# f2838x_usb_regs register map
Vendor: Texas Instruments
Peripheral module from a debugger description file (folder C2000).
Address unit: 16 bits
Registers are 8-bit, read-write, no defined reset value unless marked. A register's access mark holds for its fields unless they carry their own. Offsets are as the file gives them; lines under a group give offsets from that group; [hi:lo] are bit positions; {n}, {i} and the like mark numbered series; 'fields as' and 'values as' point back to an identical list; <NAME> marks a mode.

## USB_REGS — USB Registers
0x00 USBFADDR — USB Device Functional Address
  [6:0] FUNCADDR — Functional Address
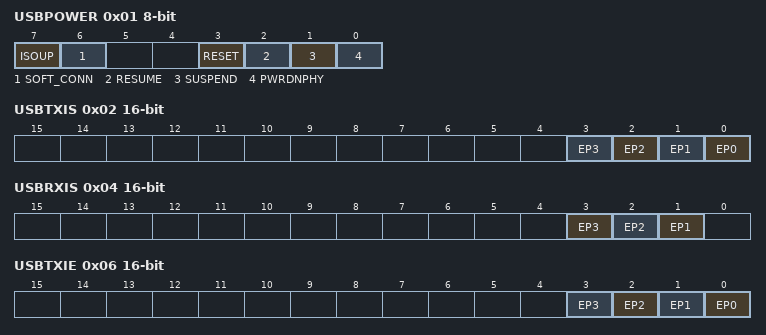
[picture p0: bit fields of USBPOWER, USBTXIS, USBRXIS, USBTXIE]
0x01 USBPOWER
  [7] ISOUP — Isochronous Update
  [6] SOFT_CONN — Soft Connect/Disconnect
  [3] RESET — Enable Reset Signaling
  [2] RESUME — Enable Resume Signaling
  [1] SUSPEND — Enable Suspend
  [0] PWRDNPHY — Power Down PHY
0x02 USBTXIS 16-bit ro — USB Transmit Interrupt Status
  [n] EP{n} (n=0..3) — Transmit Endpoint {n} Interrupt
0x04 USBRXIS 16-bit ro — USB Receive Interrupt Status
  [3] EP3 — Recieve Endpoint 3 Interrupt
  [2] EP2 — Recieve Endpoint 2 Interrupt
  [1] EP1 — Recieve Endpoint 1 Interrupt
0x06 USBTXIE 16-bit — USB Transmit Interrupt Enable
  [n] EP{n} (n=0..3) — Transmit Endpoint {n} Interrupt Enable
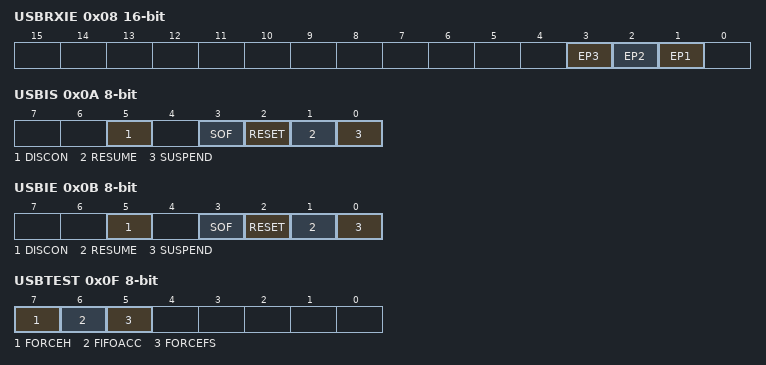
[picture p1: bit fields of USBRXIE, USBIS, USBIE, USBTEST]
0x08 USBRXIE 16-bit — USB Receive Interrupt Enable
  [3] EP3 — Recieve Endpoint 3 Interrupt Enable
  [2] EP2 — Recieve Endpoint 2 Interrupt Enable
  [1] EP1 — Recieve Endpoint 1 Interrupt Enable
0x0A USBIS access per field — USB General Interrupt Status
  [5] DISCON rw — Session Disconnect
  [3] SOF rw — Start of frame
  [2] RESET rw — RESET Signaling Detected
  [1] RESUME rw — RESUME Signaling Detected.
  [0] SUSPEND ro — SUSPEND Signaling Detected
0x0B USBIE access per field — USB Interrupt Enable
  fields as USBIS
0x0C USBFRAME 16-bit ro — USB Frame Value
  [10:0] FRAME — Frame Number
0x0E USBEPIDX — USB Endpoint Index
  [3:0] EPIDX — Endpoint Index
0x0F USBTEST — USB Test Mode
  [7] FORCEH — Force Host Mode
  [6] FIFOACC — FIFO Access
  [5] FORCEFS — Force Full Speed Upon Reset
{0x20+4i} USBFIFO{i} 32-bit (i=0..3) — USB FIFO Endpoint {i}
  [31:0] EPDATA — Endpoint Data.
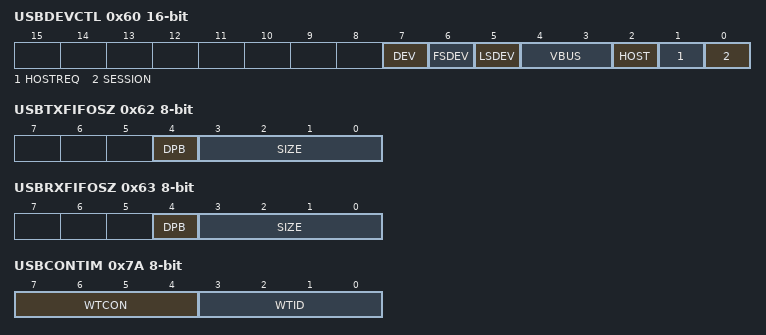
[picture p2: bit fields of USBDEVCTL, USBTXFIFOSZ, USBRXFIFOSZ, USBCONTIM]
0x60 USBDEVCTL 16-bit access per field — USB Device Control
  [7] DEV ro — Device Mode
  [6] FSDEV rw — Full Speed Device Detected
  [5] LSDEV ro — Low Speed Device Detected
  [4:3] VBUS rw — Vbus Level
  [2] HOST rw — Host Mode
  [1] HOSTREQ rw — Host Request
  [0] SESSION ro — Session Start/End
0x62 USBTXFIFOSZ access per field — USB Transmit Dynamic FIFO Sizing
  [4] DPB rw — Double Packet Buffer Support
  [3:0] SIZE ro — Max Packet Size
0x63 USBRXFIFOSZ access per field — USB Receive Dynamic FIFO Sizing
  fields as USBTXFIFOSZ
0x64 USBTXFIFOADD 16-bit — USB Transmit FIFO Start Address
  [8:0] ADDR — Endpoint Data
0x66 USBRXFIFOADD 16-bit — USB Receive FIFO Start Address
  [8:0] ADDR — Endpoint Data
0x7A USBCONTIM — USB Connect Timing
  [7:4] WTCON — Connect Wait
  [3:0] WTID — Wait ID
0x7D USBFSEOF — USB Full-Speed Last Transaction to End of Frame Timing
  [7:0] FSEOFG — The full-speed end-of-frame gap field
0x7E USBLSEOF — USB Low-Speed Last Transaction to End of Frame Timing
  [7:0] LSEOFG — The low-speed end-of-frame gap field
{0x80+8i} USBTXFUNCADDR{i} (i=0..3) — USB Transmit Functional Address Endpoint {i}
  [6:0] ADDR — Device Address
{0x82+8i} USBTXHUBADDR{i} (i=0..3) — USB Transmit Hub Address Endpoint {i}
  [6:0] ADDR — Hub Address
{0x83+8i} USBTXHUBPORT{i} (i=0..3) — USB Transmit Hub Port Endpoint {i}
  [6:0] ADDR — Hub Port
{0x84+8i} USBRXFUNCADDR{i} (i=1..3) — USB Receive Functional Address Endpoint {i}
  [6:0] ADDR — Device Address
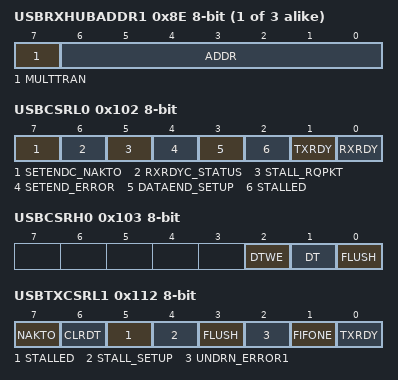
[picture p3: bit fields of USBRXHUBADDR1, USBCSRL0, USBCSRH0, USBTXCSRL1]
{0x86+8i} USBRXHUBADDR{i} (i=1..3) — USB Receive Hub Address Endpoint {i}
  [7] MULTTRAN — Hub has Multiple Translators
  [6:0] ADDR — Hub Address
{0x87+8i} USBRXHUBPORT{i} (i=1..3) — USB Receive Hub Port Endpoint {i}
  [6:0] ADDR — Hub Address
0x102 USBCSRL0 — USB Control and Status Endpoint 0 Low
  [7] SETENDC_NAKTO — Setup End Clear/NAK Timeout
  [6] RXRDYC_STATUS — RXRDY Clear/STATUS Packet
  [5] STALL_RQPKT — Send Stall /Request Packet
  [4] SETEND_ERROR — Setup End/Error
  [3] DATAEND_SETUP — Data End/Setup Packet
  [2] STALLED — Endpoint Stalled
  [1] TXRDY — Transmit Packet Ready
  [0] RXRDY — Receive Packet Ready
0x103 USBCSRH0 — USB Control and Status Endpoint 0 High
  [2] DTWE — Data Toggle Write Enable
  [1] DT — Data Toggle
  [0] FLUSH — Flush FIFO
0x108 USBCOUNT0 — USB Receive Byte Count Endpoint 0
  [6:0] COUNT — FIFO Count
0x10A USBTYPE0 — USB Type Endpoint 0
  [7:6] SPEED — Operating Speed
0x10B USBNAKLMT — USB NAK Limit
  [4:0] NAKLMT — EP0 NAK Limit
{0x100+0x10*i} USBTXMAXP{i} 16-bit (i=1..3) — USB Maximum Transmit Data Endpoint {i}
  [10:0] MAXLOAD — Maximum Payload
0x112 USBTXCSRL1 — USB Transmit Control and Status Endpoint 1 Low
  [7] NAKTO — NAK Timeout
  [6] CLRDT — Clear Data Toggle
  [5] STALLED — Endpoint Stalled
  [4] STALL_SETUP — Send Stall/Setup Packet
  [3] FLUSH — Flush FIFO
  [2] UNDRN_ERROR1 — Underun/Error
  [1] FIFONE — FIFO Not Empty
  [0] TXRDY — Transmit Packet Ready
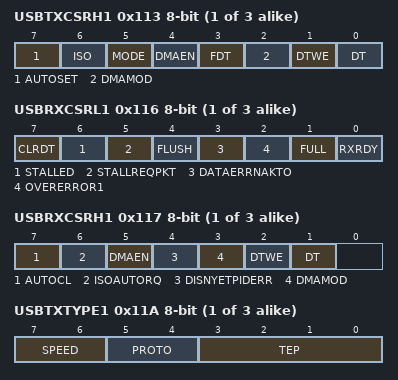
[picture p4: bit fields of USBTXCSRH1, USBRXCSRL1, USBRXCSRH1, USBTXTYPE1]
{0x103+0x10*i} USBTXCSRH{i} (i=1..3) — USB Transmit Control and Status Endpoint {i} High
  [7] AUTOSET
  [6] ISO — Isochronous Transfers
  [5] MODE
  [4] DMAEN — DMA Request Enable
  [3] FDT — Force Data Toggle
  [2] DMAMOD — DMA Request Mode
  [1] DTWE — Data Toggle Write Enable
  [0] DT — Data Toggle
{0x104+0x10*i} USBRXMAXP{i} 16-bit (i=1..3) — USB Maximum Receive Data Endpoint {i}
  [10:0] MAXLOAD — Maximum Payload
{0x106+0x10*i} USBRXCSRL{i} (i=1..3) — USB Receive Control and Status Endpoint {i} Low
  [7] CLRDT — Clear Data Toggle
  [6] STALLED — Endpoint Stalled
  [5] STALLREQPKT — Send Stall/Request Packet
  [4] FLUSH — Flush FIFO
  [3] DATAERRNAKTO — Data Error/NAK Timeout
  [2] OVERERROR{i} — Overrun/Error
  [1] FULL — FIFO Full
  [0] RXRDY — Recieve Packet Ready
{0x107+0x10*i} USBRXCSRH{i} (i=1..3) — USB Receive Control and Status Endpoint {i} High
  [7] AUTOCL — Auto Clear
  [6] ISOAUTORQ — Isochronous Transfers/Auto Request
  [5] DMAEN — DMA Request Enable
  [4] DISNYETPIDERR — Disable NYET / PID Error
  [3] DMAMOD — DMA Request Mode
  [2] DTWE — Data Toggle Write Enable
  [1] DT — Data Toggle
{0x108+0x10*i} USBRXCOUNT{i} 16-bit ro (i=1..3) — USB Receive Byte Count Endpoint {i}
  [12:0] COUNT — Receive Packet Count
{0x10A+0x10*i} USBTXTYPE{i} (i=1..3) — USB Host Transmit Configure Type Endpoint {i}
  [7:6] SPEED — Operating Speed
  [5:4] PROTO — Protocol
  [3:0] TEP — Target Endpoint Number
{0x10B+0x10*i} USBTXINTERVAL{i} (i=1..3) — USB Host Transmit Interval Endpoint {i}
  [7:0] TXPOLLNAKLMT — TX Polling / NAK Limit
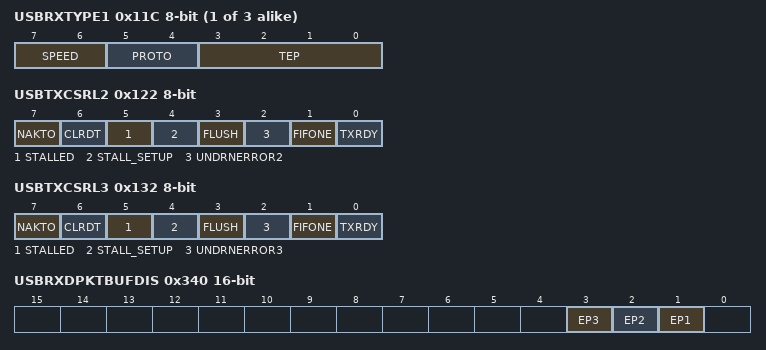
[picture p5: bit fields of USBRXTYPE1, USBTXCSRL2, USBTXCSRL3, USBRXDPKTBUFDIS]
{0x10C+0x10*i} USBRXTYPE{i} (i=1..3) — USB Host Configure Receive Type Endpoint {i}
  fields as USBTXTYPE1
{0x10D+0x10*i} USBRXINTERVAL{i} (i=1..3) — USB Host Receive Polling Interval Endpoint {i}
  [7:0] RXPOLLNAKLMT — RX Polling / NAK Limit
0x122 USBTXCSRL2 — USB Transmit Control and Status Endpoint 2 Low
  [7] NAKTO — NAK Timeout
  [6] CLRDT — Clear Data Toggle
  [5] STALLED — Endpoint Stalled
  [4] STALL_SETUP — Send Stall/Setup Packet
  [3] FLUSH — Flush FIFO
  [2] UNDRNERROR2 — Underun/Error
  [1] FIFONE — FIFO Not Empty
  [0] TXRDY — Transmit Packet Ready
0x132 USBTXCSRL3 — USB Transmit Control and Status Endpoint 3 Low
  [7] NAKTO — NAK Timeout
  [6] CLRDT — Clear Data Toggle
  [5] STALLED — Endpoint Stalled
  [4] STALL_SETUP — Send Stall/Setup Packet
  [3] FLUSH — Flush FIFO
  [2] UNDRNERROR3 — Underun/Error
  [1] FIFONE — FIFO Not Empty
  [0] TXRDY — Transmit Packet Ready
{0x300+4i} USBRQPKTCOUNT{i} 16-bit (i=1..3) — USB Request Packet Count in Block Transfer Endpoint {i}
  [12:0] COUNT — FIFO Count
0x340 USBRXDPKTBUFDIS 16-bit ro — USB Receive Double Packet Buffer Disable
  [3] EP3 — EP3 RX Double Packet Buffer Disable
  [2] EP2 — EP2 RX Double Packet Buffer Disable
  [1] EP1 — EP1 RX Double Packet Buffer Disable
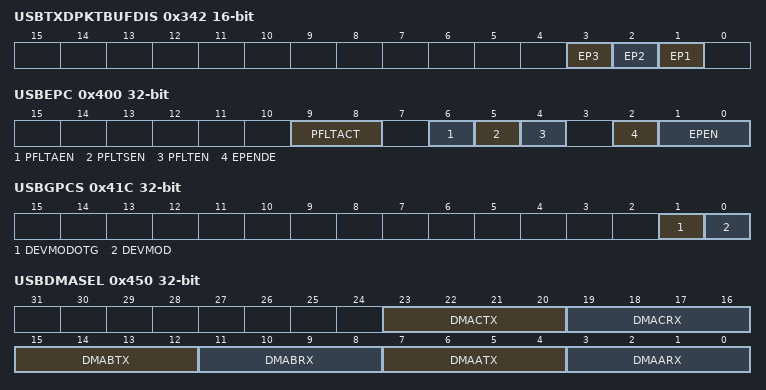
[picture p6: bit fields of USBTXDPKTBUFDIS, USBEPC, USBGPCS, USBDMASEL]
0x342 USBTXDPKTBUFDIS 16-bit ro — USB Transmit Double Packet Buffer Disable
  [3] EP3 — EP3 TX Double Packet Buffer Disable
  [2] EP2 — EP2 TX Double Packet Buffer Disable
  [1] EP1 — EP1 TX Double Packet Buffer Disable
0x400 USBEPC 32-bit — USB External Power Control
  [9:8] PFLTACT — Power Fault Action
  [6] PFLTAEN — Power Fault Action Enable
  [5] PFLTSEN — Power Fault Sense
  [4] PFLTEN — Power Fault Input Enable
  [2] EPENDE — EPEN Drive Enable
  [1:0] EPEN — External Power Supply Enable Configuration
0x404 USBEPCRIS 32-bit ro — USB External Power Control Raw Interrupt Status
  [0] PF — Power Fault Interrupt Status
0x408 USBEPCIM 32-bit ro — USB External Power Control Interrupt Mask
  [0] PF — Power Fault Interrupt Mask
0x40C USBEPCISC 32-bit ro — USB External Power Control Interrupt Status and Clear
  [0] PF — Power Fault Interrupt Status and Clear
0x410 USBDRRIS 32-bit ro — USB Device RESUME Raw Interrupt Status
  [0] RESUME — Resume Interrupt Status
0x414 USBDRIM 32-bit ro — USB Device RESUME Interrupt Mask
  [0] RESUME — Resume Interrupt Mask
0x418 USBDRISC 32-bit — USB Device RESUME Interrupt Status and Clear
  [0] RESUME — Resume Interrupt Status and Clear
0x41C USBGPCS 32-bit — USB General-Purpose Control and Status
  [1] DEVMODOTG — Enable Device Mode
  [0] DEVMOD — Device Mode
0x430 USBVDC 32-bit — USB VBUS Droop Control
  [0] VBDEN — Vbus Droop Enable
0x434 USBVDCRIS 32-bit ro — USB VBUS Droop Control Raw Interrupt Status
  [0] VD — Vbus Droop Raw Interrupt Status
0x438 USBVDCIM 32-bit ro — USB VBUS Droop Control Interrupt Mask
  [0] VD — Vbus Droop Interrupt Mask
0x43C USBVDCISC 32-bit — USB VBUS Droop Control Interrupt Status and Clear
  [0] VD — Vbus Droop Interrupt Status and Clear
0x444 USBIDVRIS 32-bit — USB ID Valid Detect Raw Interrupt Status
  [0] ID — ID Valid Detect Raw Interrupt Status
0x448 USBIDVIM 32-bit — USB ID Valid Detect Interrupt Mask
  [0] ID — ID Valid Detect Interrupt mask
0x44C USBIDVISC 32-bit — USB ID Valid Detect Interrupt Status and Clear
  [0] ID — ID Valid Detect Interrupt Status and Clear
0x450 USBDMASEL 32-bit — USB DMA Select
  [23:20] DMACTX — DMA C TX Select
  [19:16] DMACRX — DMA C RX Select
  [15:12] DMABTX — DMA B TX Select
  [11:8] DMABRX — DMA B RX Select
  [7:4] DMAATX — DMA A TX Select
  [3:0] DMAARX — DMA A RX Select
0x480 USB_GLB_INT_EN 32-bit — USB Global Interrupt Enable Register[[br]]Note: This Register is applicable only when USB is mapped to CPU1
  [0] INTEN — Global Interrupt Enable
0x484 USB_GLB_INT_FLG 32-bit — USB Global Interrupt Flag Register[[br]]Note: This Register is applicable only when USB is mapped to CPU1
  [0] INTFLG — Global Interrupt Flag
0x488 USB_GLB_INT_FLG_CLR 32-bit — USB Global Interrupt Flag Clear Register[[br]]Note: This Register is applicable only when USB is mapped to CPU1
  [0] INTFLG — Global Interrupt Flag Clear
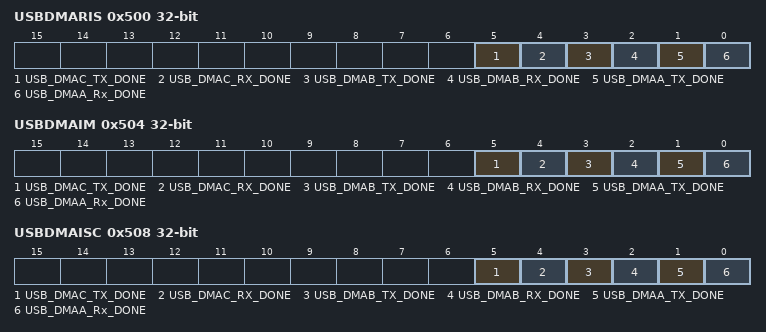
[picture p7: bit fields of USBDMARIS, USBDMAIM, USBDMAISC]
0x500 USBDMARIS 32-bit ro — USB uDMA Raw Interrupt Status register.[[br]]Note: This Register is applicable only when USB is mapped to CM
  [5] USB_DMAC_TX_DONE — DMA Tx done interrupt for DMAC
  [4] USB_DMAC_RX_DONE — DMA Rx done interrupt for DMAC
  [3] USB_DMAB_TX_DONE — DMA Tx done interrupt for DMAB
  [2] USB_DMAB_RX_DONE — DMA Rx done interrupt for DMAB
  [1] USB_DMAA_TX_DONE — DMA Tx done interrupt for DMAA
  [0] USB_DMAA_Rx_DONE — DMA Rx done interrupt for DMAA
0x504 USBDMAIM 32-bit — USB uDMA Interrupt Mask Register[[br]]Note: This Register is applicable only when USB is mapped to CM
  [5] USB_DMAC_TX_DONE — DMA Tx done interrupt mask for DMAC
  [4] USB_DMAC_RX_DONE — DMA Rx done interrupt mask for DMAC
  [3] USB_DMAB_TX_DONE — DMA Tx done interrupt mask for DMAB
  [2] USB_DMAB_RX_DONE — DMA Rx done interrupt mask for DMAB
  [1] USB_DMAA_TX_DONE — DMA Tx done interrupt mask for DMAA
  [0] USB_DMAA_Rx_DONE — DMA Rx done interrupt mask for DMAA
0x508 USBDMAISC 32-bit — USB uDMA Interrupt Status and Clear Register[[br]]Note: This Register is applicable only when USB is mapped to CM
  fields as USBDMAIM
